# CC1314R10 register map
File version: 1.0
CPU: CM33 1.0, other endian, MPU, FPU, 3 interrupt priority bits
Registers are 32-bit, read-write, reset 0x0 unless marked. A register's access mark holds for its fields unless they carry their own. Offsets are from the block's base; [hi:lo] are bit positions; 'fields as' and 'values as' point back to an identical list.

## NVMNW (part 1 of 2)
Base 0x58032000
0x20 IIDX — Interrupt Index Register: The IIDX register provides the highest priority enabled interrupt index. PSD compliant register. Note that it is not recommended to use this register if the system clock is running at a slower clock frequency than the NoWrapper clock. If this is the case, then reading this register may fail to update the RIS register correctly. The MIS register should be read directly, and a write to ICLR should be used to clear interrupts when this clock relationship is present.
  [0] STAT ro — [0:0] Indicates which interrupt has fired. 0x0 means no event pending. The priority order is fixed. On each read, only one interrupt is indicated. On a read, the current interrupt (highest priority) is automatically cleared by the hardware and the corresponding interrupt flags in the RIS and MIS are cleared as well. After a read from the CPU (not from the debug interface), the register must be updated with the next highest priority interrupt.
    1=DONE (DONE Interrupt Pending); 0=NO_INTR (No Interrupt Pending)
0x28 IMASK — Interrupt Mask Register: The IMASK register holds the current interrupt mask settings. Masked interrupts are read in the MIS register. PSD compliant register.
  [0] DONE — [0:0] Interrupt mask for DONE: 0: Interrupt is disabled in MIS register 1: Interrupt is enabled in MIS register
    1=ENABLED (Interrupt will request an interrupt service routine and corresponding bit in IPSTANDARD.MIS will be set); 0=DISABLED (Interrupt is masked out)
0x30 RIS — Raw Interrupt Status Register: The RIS register reflects all pending interrupts, regardless of masking. The RIS register allows the user to implement a poll scheme. A flag set in this register can be cleared by writing a 1 to the ICLR register bit even if the corresponding IMASK bit is not enabled. A flag can be set by software by writing a 1 to the ISET register. Reading the IIDX register will also clear the corresponding bit in RIS. PSD compliant register.
  [0] DONE ro — [0:0] NoWrapper operation completed. This interrupt bit is set by firmware or the corresponding bit in the ISET register. It is cleared by the corresponding bit in in the ICLR register or reading the IIDX register when this interrupt is the highest priority.
    1=SET (Interrupt occurred); 0=CLR (Interrupt did not occur)
0x38 MIS — Masked Interrupt Status Register: The MIS register is a bit-wise AND of the contents of the IMASK and RIS registers. This is kept mainly for ARM compatibility, and has limited use since the highest priority interrupt index is returned via the IIDX register. PSD compliant register.
  [0] DONE ro — [0:0] NoWrapper operation completed. This masked interrupt bit reflects the bitwise AND of the corresponding RIS and IMASK bits.
    1=SET (Masked interrupt occurred); 0=CLR (Masked interrupt did not occur)
0x40 ISET — Interrupt Set Register: The ISET register allows software to write a 1 to set corresponding interrupt. Safety: This meets a safety requirement to allow software diagnostics to trigger interrupts. PSD compliant register.
  [0] DONE wo — [0:0] 0: No effect 1: Set the DONE interrupt in the RIS register
    1=SET (Set IPSTANDARD.RIS bit); 0=NO_EFFECT (Writing a 0 has no effect)
0x48 ICLR — Interrupt Clear Register. The ICLR register allows allows software to write a 1 to clear corresponding interrupt. PSD compliant register.
  [0] DONE wo — [0:0] 0: No effect 1: Clear the DONE interrupt in the RIS register
    1=CLR (Clear IPSTANDARD.RIS bit); 0=NO_EFFECT (Writing a 0 has no effect)
0xE0 EVT_MODE reset 0x1 — Event mode register. It is used to select whether each line is disabled, in software mode (software clears the RIS) or in hardware mode (hardware clears the RIS).
  [1:0] INT0_CFG ro — [1:0] Event line mode select for peripheral event
    2=HARDWARE (The interrupt or event line is in hardware mode. Hardware should clear the RIS.); 1=SOFTWARE (The interrupt or event line is in software mode. Software must clear the RIS.); 0=DISABLE (The interrupt or event line is disabled.)
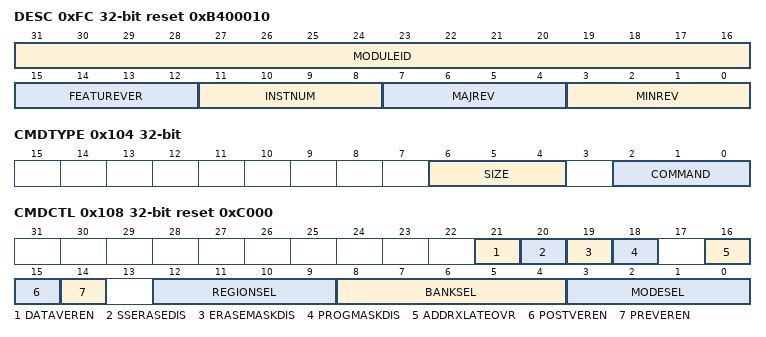
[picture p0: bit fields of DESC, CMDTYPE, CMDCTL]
0xFC DESC reset 0xB400010 — Hardware Version Description Register: This register identifies the NoWrapper hardware version and feature set used.
  [31:16] MODULEID ro — [31:16] Module ID
    0xFFFF=MAXIMUM (Highest possible value); 0=MINIMUM (Smallest value)
  [15:12] FEATUREVER ro — [15:12] Feature set
    15=MAXIMUM (Maximum Value); 0=MINIMUM (Minimum Value)
  [11:8] INSTNUM ro — [11:8] Instance number
    15=MAXIMUM (Highest possible value); 0=MINIMUM (Smallest value)
  [7:4] MAJREV ro — [7:4] Major Revision
    values as INSTNUM
  [3:0] MINREV ro — [3:0] Minor Revision
    values as INSTNUM
0x100 CMDEXEC — Command Execute Register: Initiates execution of the command specified in the CMDTYPE register. This register is blocked for writes after being written to 1 and prior to STATCMD.DONE being set by the NoWrapper hardware. NoWrapper hardware clears this register after the processing of the command has completed.
  [0] VAL — [0:0] Command Execute value Initiates execution of the command specified in the CMDTYPE register.
    1=EXECUTE (Command will execute or is executing in NoWrapper); 0=NOEXECUTE (Command will not execute or is not executing in NoWrapper)
0x104 CMDTYPE — Command Type Register This register specifies the type of command to be executed by the NoWrapper hardware. This register is blocked for writes after CMDEXEC is written to a 1 and prior to STATCMD.DONE being set by the hardware to indicate that command execution has completed.
  [6:4] SIZE — [6:4] Command size
    5=BANK (Operate on an entire flash bank); 4=SECTOR (Operate on a flash sector); 3=EIGHTWORD (Operate on 8 flash words); 2=FOURWORD (Operate on 4 flash words); 1=TWOWORD (Operate on 2 flash words); 0=ONEWORD (Operate on 1 flash word)
  [2:0] COMMAND — [2:0] Command type
    6=BLANKVERIFY (Blank Verify - Check whether a flash word is in the erased state. This command may only be used with CMDTYPE.SIZE = ONEWORD); 5=CLEARSTATUS (Clear Status - Clear status bits in FW_SMSTAT only.); 4=MODECHANGE (Mode Change - Perform a mode change only, no other operation.); 3=READVERIFY (Read Verify - Perform a standalone read verify operation.); 2=ERASE; 1=PROGRAM; 0=NOOP (No Operation)
0x108 CMDCTL reset 0xC000 — Command Control Register This register configures specific capabilities of the state machine for related to the execution of a command. This register is blocked for writes after CMDEXEC is written to a 1 and prior to STATCMD.DONE being set by the hardware to indicate that command execution has completed.
  [21] DATAVEREN — [21:21] Enable invalid data verify. This checks for 0->1 transitions in the memory when a program operation is initiated. If such a transition is found, the program will fail with an error without doing any programming.
    1=ENABLE; 0=DISABLE
  [20] SSERASEDIS — [20:20] Disable Stair-Step Erase. If set, the default VHV trim voltage setting will be used for all erase pulses. By default, this bit is reset, meaning that the VHV voltage will be stepped during successive erase pulses. The step count, step voltage, begin and end voltages are all hard-wired.
    1=DISABLE; 0=ENABLE
  [19] ERASEMASKDIS — [19:19] Disable use of erase mask for erase Bit masking will not be used during erase verify. If any sectors fail the verify either before (prever) or after (postver) the operation, then all specified flash sectors will receive subsequent erase pulse.
    1=DISABLE; 0=ENABLE
  [18] PROGMASKDIS — [18:18] Disable use of program mask for programming. Bit masking will not be used during program verify. If any bits fail the verify either before (prever) or after (postver) the operation, then all specified flash entries will receive subsequent program pulse.
    1=DISABLE; 0=ENABLE
  [16] ADDRXLATEOVR — [16:16] Override hardware address translation of address in CMDADDR from a system address to a bank address and bank ID. Use data written to CMDADDR directly as the bank address. Use the value written to CMDCTL.BANKSEL directly as the bank ID. Use the value written to CMDCTL.REGIONSEL directly as the region ID.
    1=OVERRIDE; 0=NOOVERRIDE (Do not override)
  [15] POSTVEREN — [15:15] Enable verify after program or erase
    1=ENABLE; 0=DISABLE
  [14] PREVEREN — [14:14] Enable verify before program or erase. For program, bits already programmed to the requested value will be masked. For erase, sectors already erased will be masked.
    1=ENABLE; 0=DISABLE
  [12:9] REGIONSEL — [12:9] Bank Region A specific region ID can be written to this field to indicate to which region an operation should be applied if CMDCTL.ADDRXLATEOVR is set.
    8=ENGR (Engr Region); 4=TRIM (Trim Region); 2=NONMAIN (Non-Main Region); 1=MAIN (Main Region)
  [8:4] BANKSEL — [8:4] Bank Select A specific Bank ID can be written to this field to indicate to which bank an operation should be applied if CMDCTL.ADDRXLATEOVR is set.
    16=BANK4; 8=BANK3; 4=BANK2; 2=BANK1; 1=BANK0
  [3:0] MODESEL — [3:0] Mode This field is only used for the Mode Change command type. Otherwise, bank and pump modes are set automaticlly via the NW hardware.
    15=ERASEBNK (Erase Bank); 14=PGMMW (Program Multiple Word); 12=ERASESECT (Erase Sector); 11=ERASEVER (Erase Verify Mode); 10=PGMSW (Program Single Word); 9=PGMVER (Program Verify Mode); 7=RDMARG1B (Read Margin 1B Mode); 6=RDMARG0B (Read Margin 0B Mode); 4=RDMARG1 (Read Margin 1 Mode); 2=RDMARG0 (Read Margin 0 Mode); 0=READ (Read Mode)
0x120 CMDADDR — Command Address Register: This register forms the target address of a command. The use cases are as follows: 1)For single-word program, this address indicates the flash bank word to be programmed. 2)For multi-word program, this address indicates the first flash bank address for the program. The address will be incremented for further words. 3)For sector erase, this address indicates the sector to be erased. 4)For bank erase, the address indicates the bank to be erased. 5)For read verify, the address indications follow program/erase listed above. Note the address written to this register will be submitted for translation to the NoWrapper address translation interface, and the translated address will be used to access the bank. However, if the CMDCTL.ADDRXLATEOVR bit is set, then the address written to this register will be used directly as the bank address. This register is blocked for writes after a 1 is written to the CMDEXEC register and prior to STATCMD.DONE being set by the NoWrapper hardware.
  [31:0] VAL — [31:0] Address value
    0xFFFFFFFF=MAXIMUM (Maximum value of VAL); 0=MINIMUM (Minimum value of VAL)
0x124 CMDBYTEN reset 0xFFFF — Command Program Byte Enable Register: This register forms a per-byte enable for programming data. For data bytes to be programmed, a 1 must be written to the corresponding bit in this register. Normally, all bits are written to 1, allowing program of full flash words. However, leaving some bits 0 allows programming of 8-bit, 16-bit, 32-bit or 64-bit portions of a flash word. In addtion, the read verify command will ignore data bytes read from the flash in its comparison if the corresponding CMDBYTEN bit is 0. ECC data bytes are protected by the 1-2 MSB bits in this register, depending on the presence of ECC and the flash word data width. This register is blocked for writes after a 1 is written to the CMDEXEC register and prior to STATCMD.DONE being set by the NoWrapper hardware. This register is written to all 0 after the completion of all NoWrapper commands.
  [15:0] VAL — [15:0] Command Byte Enable value. A 1-bit per flash word byte value is placed in this register.
    0xFFFF=MAXIMUM (Maximum value of VAL); 0=MINIMUM (Minimum value of VAL)
0x12C CMDDATAINDEX — Command Program Data Index Register: When multiple data registers are available for multi-word program, this register can be written with an index which points to one of the data registers. When a write to CMDDATA* is done, the data will be written to the physical data register indexed by the value in this register. Up to 8 data registers can be present, so this register can be written with 0x0 to 0x7. If less than 8 data registers are present, successive MSB bits of this register are ignored when indexing the CMDDATA* registers. This register is blocked for writes after a 1 is written to the CMDEXEC register and prior to STATCMD.DONE being set by the NoWrapper hardware.
  [1:0] VAL — [1:0] Data register index
    3=MAXIMUM (Maximum value of VAL); 0=MINIMUM (Minimum value of VAL)
0x130 CMDDATA0 reset 0xFFFFFFFF — Command Data Register 0 This register forms the data for a command. For DATAWIDTH == 128:This register represents bits 31:0 of flash word data register 0. For DATAWIDTH == 64:This register represents bits 31:0 of flash word data register 0. This register is blocked for writes after a 1 is written to the CMDEXEC register and prior to STATCMD.DONE being set by the NoWrapper hardware. This register is used to aggregate masking for bits that do not require additional program pulses during program operations, and will be written to all 1 after the completion of all NoWrapper commands. Use cases for the CMDDATA* registers are as follows: 1)Program - These registers contain the data to be programmed. 2)Erase - These registers are not used. 3)Read Verify - These registers contain data to be verified.
  [31:0] VAL — [31:0] A 32-bit data value is placed in this field.
    values as CMDADDR.VAL
0x134 CMDDATA1 reset 0xFFFFFFFF — Command Data Register 1 This register forms the data for a command. For DATAWIDTH == 128:This register represents bits 63:32 of flash word data register 0. For DATAWIDTH == 64:This register represents bits 63:32 of flash word data register 0. This register is blocked for writes after a 1 is written to the CMDEXEC register and prior to CMDSTAT.DONE being set by the NoWrapper hardware. This register is used to aggregate masking for bits that do not require additional program pulses during program operations, and will be written to all 1 after the completion of all NoWrapper commands. Use cases for the CMDDATA* registers are as follows: 1)Program - These registers contain the data to be programmed. 2)Erase - These registers are not used. 3)Read Verify - These registers contain data to be verified.
  fields as CMDDATA0
0x138 CMDDATA2 reset 0xFFFFFFFF — Command Data Register 2 This register forms the data for a command. For DATAWIDTH == 128:This register represents bits 95:64 of flash word data register 0. For DATAWIDTH == 64:This register represents bits 31:0 of flash word data register 1. This register is blocked for writes after a 1 is written to the CMDEXEC register and prior to STATCMD.DONE being set by the NoWrapper hardware. This register is used to aggregate masking for bits that do not require additional program pulses during program operations, and will be written to all 1 after the completion of all NoWrapper commands. Use cases for the CMDDATA* registers are as follows: 1)Program - These registers contain the data to be programmed. 2)Erase - These registers are not used. 3)Read Verify - These registers contain data to be verified.
  fields as CMDDATA0
0x13C CMDDATA3 reset 0xFFFFFFFF — Command Data Register 3 This register forms the data for a command. For DATAWIDTH == 128:This register represents bits 127:96 of flash word data register 0. For DATAWIDTH == 64:This register represents bits 63:32 of flash word data register 1. This register is blocked for writes after a 1 is written to the CMDEXEC register and prior to STATCMD.DONE being set by the NoWrapper hardware. This register is used to aggregate masking for bits that do not require additional program pulses during program operations, and will be written to all 1 after the completion of all NoWrapper commands. Use cases for the CMDDATA* registers are as follows: 1)Program - These registers contain the data to be programmed. 2)Erase - These registers are not used. 3)Read Verify - These registers contain data to be verified.
  fields as CMDDATA0
0x140 CMDDATA4 reset 0xFFFFFFFF — Command Data Register 4 This register forms the data for a command. For DATAWIDTH == 128:This register represents bits 31:0 of flash word data register 1. For DATAWIDTH == 64:This register represents bits 31:0 of flash word data register 2. This register is blocked for writes after a 1 is written to the CMDEXEC register and prior to STATCMD.DONE being set by the NoWrapper hardware. This register is used to aggregate masking for bits that do not require additional program pulses during program operations, and will be written to all 1 after the completion of all NoWrapper commands. Use cases for the CMDDATA* registers are as follows: 1)Program - These registers contain the data to be programmed. 2)Erase - These registers are not used. 3)Read Verify - These registers contain data to be verified.
  [31:0] VAL — [31:0] A 32-bit data value is placed in this field. T
    values as CMDADDR.VAL
0x144 CMDDATA5 reset 0xFFFFFFFF — Command Data Register 5 This register forms the data for a command. For DATAWIDTH == 128:This register represents bits 63:32 of flash word data register 1. For DATAWIDTH == 64:This register represents bits 63:32 of flash word data register 2. This register is blocked for writes after a 1 is written to the CMDEXEC register and prior to STATCMD.DONE being set by the NoWrapper hardware. This register is used to aggregate masking for bits that do not require additional program pulses during program operations, and will be written to all 1 after the completion of all NoWrapper commands. Use cases for the CMDDATA* registers are as follows: 1)Program - These registers contain the data to be programmed. 2)Erase - These registers are not used. 3)Read Verify - These registers contain data to be verified.
  fields as CMDDATA0
0x148 CMDDATA6 reset 0xFFFFFFFF — Command Data Register 6 This register forms the data for a command. For DATAWIDTH == 128:This register represents bits 95:64 of flash word data register 1. For DATAWIDTH == 64:This register represents bits 31:0 of flash word data register 3. This register is blocked for writes after a 1 is written to the CMDEXEC register and prior to STATCMD.DONE being set by the NoWrapper hardware. This register is used to aggregate masking for bits that do not require additional program pulses during program operations, and will be written to all 1 after the completion of all NoWrapper commands. Use cases for the CMDDATA* registers are as follows: 1)Program - These registers contain the data to be programmed. 2)Erase - These registers are not used. 3)Read Verify - These registers contain data to be verified.
  fields as CMDDATA0
0x14C CMDDATA7 reset 0xFFFFFFFF — Command Data Register 7 This register forms the data for a command. For DATAWIDTH == 128:This register represents bits 127:96 of flash word data register 1. For DATAWIDTH == 64:This register represents bits 63:32 of flash word data register 3. This register is blocked for writes after a 1 is written to the CMDEXEC register and prior to STATCMD.DONE being set by the NoWrapper hardware. This register is used to aggregate masking for bits that do not require additional program pulses during program operations, and will be written to all 1 after the completion of all NoWrapper commands. Use cases for the CMDDATA* registers are as follows: 1)Program - These registers contain the data to be programmed. 2)Erase - These registers are not used. 3)Read Verify - These registers contain data to be verified.
  fields as CMDDATA0
0x150 CMDDATA8 reset 0xFFFFFFFF — Command Data Register 8 This register forms the data for a command. For DATAWIDTH == 128:This register represents bits 31:0 of flash word data register 2. For DATAWIDTH == 64:This register represents bits 31:0 of flash word data register 4. This register is blocked for writes after a 1 is written to the CMDEXEC register and prior to STATCMD.DONE being set by the NoWrapper hardware. This register is used to aggregate masking for bits that do not require additional program pulses during program operations, and will be written to all 1 after the completion of all NoWrapper commands. Use cases for the CMDDATA* registers are as follows: 1)Program - These registers contain the data to be programmed. 2)Erase - These registers are not used. 3)Read Verify - These registers contain data to be verified.
  fields as CMDDATA0
0x154 CMDDATA9 reset 0xFFFFFFFF — Command Data Register 9 This register forms the data for a command. For DATAWIDTH == 128:This register represents bits 63:32 of flash word data register 2. For DATAWIDTH == 64:This register represents bits 63:32 of flash word data register 4. This register is blocked for writes after a 1 is written to the CMDEXEC register and prior to STATCMD.DONE being set by the NoWrapper hardware. This register is used to aggregate masking for bits that do not require additional program pulses during program operations, and will be written to all 1 after the completion of all NoWrapper commands. Use cases for the CMDDATA* registers are as follows: 1)Program - These registers contain the data to be programmed. 2)Erase - These registers are not used. 3)Read Verify - These registers contain data to be verified.
  fields as CMDDATA0
0x158 CMDDATA10 reset 0xFFFFFFFF — Command Data Register 10 This register forms the data for a command. For DATAWIDTH == 128:This register represents bits 95:64 of flash word data register 2. For DATAWIDTH == 64:This register represents bits 31:0 of flash word data register 5. This register is blocked for writes after a 1 is written to the CMDEXEC register and prior to STATCMD.DONE being set by the NoWrapper hardware. This register is used to aggregate masking for bits that do not require additional program pulses during program operations, and will be written to all 1 after the completion of all NoWrapper commands. Use cases for the CMDDATA* registers are as follows: 1)Program - These registers contain the data to be programmed. 2)Erase - These registers are not used. 3)Read Verify - These registers contain data to be verified.
  fields as CMDDATA0
0x15C CMDDATA11 reset 0xFFFFFFFF — Command Data Register 11 This register forms the data for a command. For DATAWIDTH == 128:This register represents bits 127:96 of flash word data register 2. For DATAWIDTH == 64:This register represents bits 63:32 of flash word data register 5. This register is blocked for writes after a 1 is written to the CMDEXEC register and prior to STATCMD.DONE being set by the NoWrapper hardware. This register is used to aggregate masking for bits that do not require additional program pulses during program operations, and will be written to all 1 after the completion of all NoWrapper commands. Use cases for the CMDDATA* registers are as follows: 1)Program - These registers contain the data to be programmed. 2)Erase - These registers are not used. 3)Read Verify - These registers contain data to be verified.
  fields as CMDDATA0
0x160 CMDDATA12 reset 0xFFFFFFFF — Command Data Register 12 This register forms the data for a command. For DATAWIDTH == 128:This register represents bits 31:0 of flash word data register 3. For DATAWIDTH == 64:This register represents bits 31:0 of flash word data register 6. This register is blocked for writes after a 1 is written to the CMDEXEC register and prior to STATCMD.DONE being set by the NoWrapper hardware. This register is used to aggregate masking for bits that do not require additional program pulses during program operations, and will be written to all 1 after the completion of all NoWrapper commands. Use cases for the CMDDATA* registers are as follows: 1)Program - These registers contain the data to be programmed. 2)Erase - These registers are not used. 3)Read Verify - These registers contain data to be verified.
  fields as CMDDATA0
0x164 CMDDATA13 reset 0xFFFFFFFF — Command Data Register 13 This register forms the data for a command. For DATAWIDTH == 128:This register represents bits 63:32 of flash word data register 3. For DATAWIDTH == 64:This register represents bits 63:32 of flash word data register 6. This register is blocked for writes after a 1 is written to the CMDEXEC register and prior to STATCMD.DONE being set by the NoWrapper hardware. This register is used to aggregate masking for bits that do not require additional program pulses during program operations, and will be written to all 1 after the completion of all NoWrapper commands. Use cases for the CMDDATA* registers are as follows: 1)Program - These registers contain the data to be programmed. 2)Erase - These registers are not used. 3)Read Verify - These registers contain data to be verified.
  fields as CMDDATA0
0x168 CMDDATA14 reset 0xFFFFFFFF — Command Data Register 14 This register forms the data for a command. For DATAWIDTH == 128:This register represents bits 95:64 of flash word data register 3. For DATAWIDTH == 64:This register represents bits 31:0 of flash word data register 7. This register is blocked for writes after a 1 is written to the CMDEXEC register and prior to STATCMD.DONE being set by the NoWrapper hardware. This register is used to aggregate masking for bits that do not require additional program pulses during program operations, and will be written to all 1 after the completion of all NoWrapper commands. Use cases for the CMDDATA* registers are as follows: 1)Program - These registers contain the data to be programmed. 2)Erase - These registers are not used. 3)Read Verify - These registers contain data to be verified.
  fields as CMDDATA0
